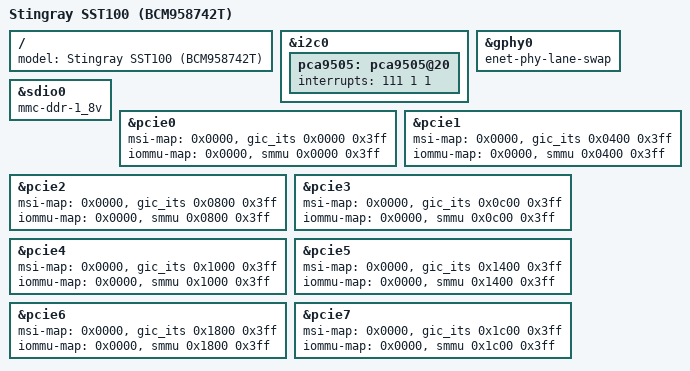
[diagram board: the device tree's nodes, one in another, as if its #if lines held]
/*
 *  BSD LICENSE
 *
 *  Copyright(c) 2017 Broadcom.  All rights reserved.
 *
 *  Redistribution and use in source and binary forms, with or without
 *  modification, are permitted provided that the following conditions
 *  are met:
 *
 *    * Redistributions of source code must retain the above copyright
 *      notice, this list of conditions and the following disclaimer.
 *    * Redistributions in binary form must reproduce the above copyright
 *      notice, this list of conditions and the following disclaimer in
 *      the documentation and/or other materials provided with the
 *      distribution.
 *    * Neither the name of Broadcom nor the names of its
 *      contributors may be used to endorse or promote products derived
 *      from this software without specific prior written permission.
 *
 *  THIS SOFTWARE IS PROVIDED BY THE COPYRIGHT HOLDERS AND CONTRIBUTORS
 *  "AS IS" AND ANY EXPRESS OR IMPLIED WARRANTIES, INCLUDING, BUT NOT
 *  LIMITED TO, THE IMPLIED WARRANTIES OF MERCHANTABILITY AND FITNESS FOR
 *  A PARTICULAR PURPOSE ARE DISCLAIMED. IN NO EVENT SHALL THE COPYRIGHT
 *  OWNER OR CONTRIBUTORS BE LIABLE FOR ANY DIRECT, INDIRECT, INCIDENTAL,
 *  SPECIAL, EXEMPLARY, OR CONSEQUENTIAL DAMAGES (INCLUDING, BUT NOT
 *  LIMITED TO, PROCUREMENT OF SUBSTITUTE GOODS OR SERVICES; LOSS OF USE,
 *  DATA, OR PROFITS; OR BUSINESS INTERRUPTION) HOWEVER CAUSED AND ON ANY
 *  THEORY OF LIABILITY, WHETHER IN CONTRACT, STRICT LIABILITY, OR TORT
 *  (INCLUDING NEGLIGENCE OR OTHERWISE) ARISING IN ANY WAY OUT OF THE USE
 *  OF THIS SOFTWARE, EVEN IF ADVISED OF THE POSSIBILITY OF SUCH DAMAGE.
 */

/dts-v1/;

#define NUM_CRYPTO	32
#define NUM_RAID	8
#define ENABLE_I2C0	1
#define NUM_SATA	8
#define ENABLE_DMC1	0
#define ENABLE_DMC2	0

#include "bcm958742-base.dtsi"
#include "stingray-dmc.dtsi"

/ {
	model = "Stingray SST100 (BCM958742T)";
};

&i2c0 {
	pca9505: pca9505@20 {
		interrupts = <111 1 1>;
	};
};

&gphy0 {
	enet-phy-lane-swap;
};

&sdio0 {
	mmc-ddr-1_8v;
};

&pcie0 {
	msi-map = <0x0000 &gic_its 0x0000 0x3ff>;
#if (ENABLE_PAXB_IOMMU == 1)
	iommu-map = <0x0000 &smmu 0x0000 0x3ff>;
#endif
};

&pcie1 {
        msi-map = <0x0000 &gic_its 0x0400 0x3ff>;
#if (ENABLE_PAXB_IOMMU == 1)
	iommu-map = <0x0000 &smmu 0x0400 0x3ff>;
#endif
};

&pcie2 {
        msi-map = <0x0000 &gic_its 0x0800 0x3ff>;
#if (ENABLE_PAXB_IOMMU == 1)
	iommu-map = <0x0000 &smmu 0x0800 0x3ff>;
#endif
};

&pcie3 {
        msi-map = <0x0000 &gic_its 0x0c00 0x3ff>;
#if (ENABLE_PAXB_IOMMU == 1)
	iommu-map = <0x0000 &smmu 0x0c00 0x3ff>;
#endif
};

&pcie4 {

        msi-map = <0x0000 &gic_its 0x1000 0x3ff>;
#if (ENABLE_PAXB_IOMMU == 1)
	iommu-map = <0x0000 &smmu 0x1000 0x3ff>;
#endif
};
&pcie5 {

        msi-map = <0x0000 &gic_its 0x1400 0x3ff>;

#if (ENABLE_PAXB_IOMMU == 1)
	iommu-map = <0x0000 &smmu 0x1400 0x3ff>;
#endif
};
&pcie6 {

        msi-map = <0x0000 &gic_its 0x1800 0x3ff>;
#if (ENABLE_PAXB_IOMMU == 1)
	iommu-map = <0x0000 &smmu 0x1800 0x3ff>;
#endif
};

&pcie7 {

        msi-map = <0x0000 &gic_its 0x1c00 0x3ff>;
#if (ENABLE_PAXB_IOMMU == 1)
	iommu-map = <0x0000 &smmu 0x1c00 0x3ff>;
#endif
};
